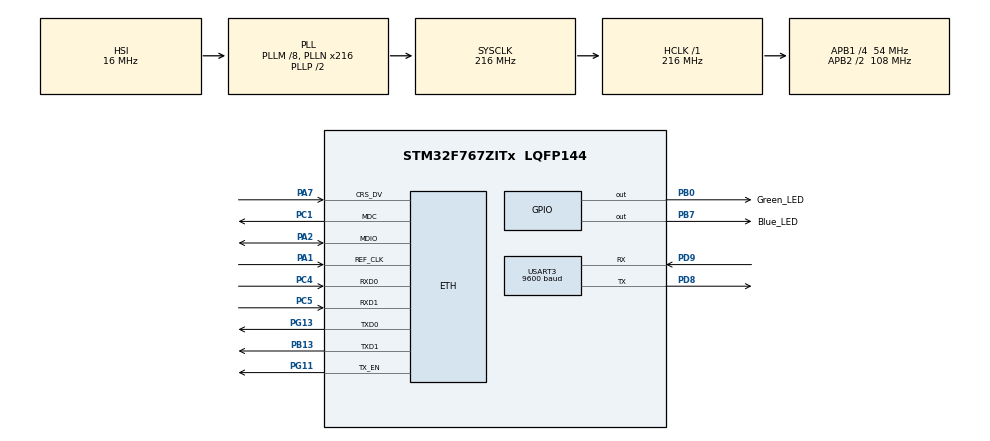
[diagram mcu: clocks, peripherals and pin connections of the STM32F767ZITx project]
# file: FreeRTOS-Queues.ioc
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ETH.MediaInterface=ETH_MEDIA_INTERFACE_RMII
ETH.PhyAddress=0
FREERTOS.Tasks01=defaultTask,24,128,StartDefaultTask,Default,NULL,Dynamic,NULL,NULL
FREERTOS.configUSE_NEWLIB_REENTRANT=1
LWIP.GATEWAY_ADDRESS=192.168.000.001
LWIP.IP_ADDRESS=192.168.000.012
LWIP.LWIP_DHCP=0
LWIP.MEM_SIZE=10*1024
LWIP.NETMASK_ADDRESS=255.255.255.000
LWIP.Version=v2.1.2_Cube
Mcu.Family=STM32F7
Mcu.Name=STM32F767ZITx
Mcu.Package=LQFP144
NVIC.ETH_IRQn=true\:5\:0\:false\:false\:true\:true\:false\:true
NVIC.PriorityGroup=NVIC_PRIORITYGROUP_4
NVIC.TIM1_UP_TIM10_IRQn=true\:15\:0\:false\:false\:true\:false\:false\:true
NVIC.TimeBase=TIM1_UP_TIM10_IRQn
NVIC.TimeBaseIP=TIM1
PA1.Mode=RMII
PA1.Signal=ETH_REF_CLK
PA2.Mode=RMII
PA2.Signal=ETH_MDIO
PA7.Mode=RMII
PA7.Signal=ETH_CRS_DV
PB0.GPIO_Label=Green_LED
PB0.Signal=GPIO_Output
PB13.Mode=RMII
PB13.Signal=ETH_TXD1
PB7.GPIO_Label=Blue_LED
PB7.Signal=GPIO_Output
PC1.Mode=RMII
PC1.Signal=ETH_MDC
PC14/OSC32_IN.Signal=RCC_OSC32_IN
PC15/OSC32_OUT.Signal=RCC_OSC32_OUT
PC4.Mode=RMII
PC4.Signal=ETH_RXD0
PC5.Mode=RMII
PC5.Signal=ETH_RXD1
PD8.Mode=Asynchronous
PD8.Signal=USART3_TX
PD9.Mode=Asynchronous
PD9.Signal=USART3_RX
PG11.Mode=RMII
PG11.Signal=ETH_TX_EN
PG13.Mode=RMII
PG13.Signal=ETH_TXD0
PH0/OSC_IN.Mode=HSE-External-Oscillator
PH0/OSC_IN.Signal=RCC_OSC_IN
PH1/OSC_OUT.Mode=HSE-External-Oscillator
PH1/OSC_OUT.Signal=RCC_OSC_OUT
ProjectManager.HeapSize=0x200
ProjectManager.StackSize=0x400
ProjectManager.TargetToolchain=STM32CubeIDE
RCC.48MHZClocksFreq_Value=24000000
RCC.AHBFreq_Value=216000000
RCC.APB1CLKDivider=RCC_HCLK_DIV4
RCC.APB1Freq_Value=54000000
RCC.APB1TimFreq_Value=108000000
RCC.APB2CLKDivider=RCC_HCLK_DIV2
RCC.APB2Freq_Value=108000000
RCC.APB2TimFreq_Value=216000000
RCC.CortexFreq_Value=216000000
RCC.HCLKFreq_Value=216000000
RCC.HSE_VALUE=16000000
RCC.HSI_VALUE=16000000
RCC.LSE_VALUE=32768
RCC.PLLM=8
RCC.PLLMUL=RCC_PLL_MUL9
RCC.PLLN=216
RCC.PRESCALERUSB=RCC_USBCLKSOURCE_PLL_DIV1_5
RCC.SYSCLKFreq_VALUE=216000000
RCC.SYSCLKSource=RCC_SYSCLKSOURCE_PLLCLK
RCC.SYSCLKSourceVirtual=RCC_SYSCLKSOURCE_PLLCLK
RCC.USBFreq_Value=216000000
RCC.VCOOutputFreq_Value=432000000
USART3.BaudRate=9600
USART3.VirtualMode-Asynchronous=VM_ASYNC
VP_FREERTOS_VS_CMSIS_V2.Mode=CMSIS_V2
VP_LWIP_VS_Enabled.Mode=Enabled
VP_SYS_VS_tim1.Mode=TIM1
board=NUCLEO-F767ZI

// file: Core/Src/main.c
/* USER CODE BEGIN Header */
/**
  ******************************************************************************
  * @file           : main.c
  * @brief          : Main program body
  ******************************************************************************
  * @attention
  *
  * <h2><center>&copy; Copyright (c) 2023 STMicroelectronics.
  * All rights reserved.</center></h2>
  *
  * This software component is licensed by ST under Ultimate Liberty license
  * SLA0044, the "License"; You may not use this file except in compliance with
  * the License. You may obtain a copy of the License at:
  *                             www.st.com/SLA0044
  *
  ******************************************************************************
  */
/* USER CODE END Header */
#include "main.h"
#include "cmsis_os.h"
#include "lwip.h"

/* USER CODE BEGIN Includes */
#include "Queue_Examples.h"

/* USER CODE END Includes */

UART_HandleTypeDef huart3;

/* Definitions for defaultTask */
osThreadId_t defaultTaskHandle;
const osThreadAttr_t defaultTask_attributes = {
  .name = "defaultTask",
  .stack_size = 128 * 4,
  .priority = (osPriority_t) osPriorityIdle,
};
/* USER CODE BEGIN PV */

TaskHandle_t receive_uart_task_handle;
TaskHandle_t send_uart_task_handle;
QueueHandle_t xQueue1 ;

/* USER CODE END PV */

void SystemClock_Config(void);
static void MX_GPIO_Init(void);
static void MX_USART3_UART_Init(void);
void StartDefaultTask(void *argument);

int main(void)
{

  /* MCU Configuration--------------------------------------------------------*/

  /* Reset of all peripherals, Initializes the Flash interface and the Systick. */
  HAL_Init();

  /* Configure the system clock */
  SystemClock_Config();

  /* Initialize all configured peripherals */
  MX_GPIO_Init();
  MX_USART3_UART_Init();

  /* Init scheduler */
  osKernelInitialize();

  /* USER CODE BEGIN RTOS_QUEUES */
  /* add queues, ... */
     xQueue1 = xQueueCreate( 5, sizeof(uint32_t));
	 if(xQueue1 == 0 )
  {
	  Error_Handler();
  }
  /* USER CODE END RTOS_QUEUES */

  /* Create the thread(s) */
  /* creation of defaultTask */
  defaultTaskHandle = osThreadNew(StartDefaultTask, NULL, &defaultTask_attributes);

  /* USER CODE BEGIN RTOS_THREADS */
  /* add threads, ... */

	  if( xTaskCreate(rcv_task,"receive_uart_task",1000,0, 1, &receive_uart_task_handle) != pdPASS)
	   {
	 	  // add an error msg
		  Error_Handler();
	   }

	  if( xTaskCreate(msg_parser,"handler_uart_parser",1000,0,1, &send_uart_task_handle) != pdPASS)
	 	   {
	 	 	  // add an error msg
		  Error_Handler();
	 	   }

  /* USER CODE END RTOS_THREADS */

  /* Start scheduler */
  osKernelStart();

  /* We should never get here as control is now taken by the scheduler */
  /* Infinite loop */
  while (1)
  {

  }
}

void SystemClock_Config(void)
{
  RCC_OscInitTypeDef RCC_OscInitStruct = {0};
  RCC_ClkInitTypeDef RCC_ClkInitStruct = {0};
  RCC_PeriphCLKInitTypeDef PeriphClkInitStruct = {0};

  /** Configure the main internal regulator output voltage
  */
  __HAL_RCC_PWR_CLK_ENABLE();
  __HAL_PWR_VOLTAGESCALING_CONFIG(PWR_REGULATOR_VOLTAGE_SCALE1);
  /** Initializes the RCC Oscillators according to the specified parameters
  * in the RCC_OscInitTypeDef structure.
  */
  RCC_OscInitStruct.OscillatorType = RCC_OSCILLATORTYPE_HSI;
  RCC_OscInitStruct.HSIState = RCC_HSI_ON;
  RCC_OscInitStruct.HSICalibrationValue = RCC_HSICALIBRATION_DEFAULT;
  RCC_OscInitStruct.PLL.PLLState = RCC_PLL_ON;
  RCC_OscInitStruct.PLL.PLLSource = RCC_PLLSOURCE_HSI;
  RCC_OscInitStruct.PLL.PLLM = 8;
  RCC_OscInitStruct.PLL.PLLN = 216;
  RCC_OscInitStruct.PLL.PLLP = RCC_PLLP_DIV2;
  RCC_OscInitStruct.PLL.PLLQ = 2;
  RCC_OscInitStruct.PLL.PLLR = 2;
  if (HAL_RCC_OscConfig(&RCC_OscInitStruct) != HAL_OK)
  {
    Error_Handler();
  }
  /** Activate the Over-Drive mode
  */
  if (HAL_PWREx_EnableOverDrive() != HAL_OK)
  {
    Error_Handler();
  }
  /** Initializes the CPU, AHB and APB buses clocks
  */
  RCC_ClkInitStruct.ClockType = RCC_CLOCKTYPE_HCLK|RCC_CLOCKTYPE_SYSCLK
                              |RCC_CLOCKTYPE_PCLK1|RCC_CLOCKTYPE_PCLK2;
  RCC_ClkInitStruct.SYSCLKSource = RCC_SYSCLKSOURCE_PLLCLK;
  RCC_ClkInitStruct.AHBCLKDivider = RCC_SYSCLK_DIV1;
  RCC_ClkInitStruct.APB1CLKDivider = RCC_HCLK_DIV4;
  RCC_ClkInitStruct.APB2CLKDivider = RCC_HCLK_DIV2;

  if (HAL_RCC_ClockConfig(&RCC_ClkInitStruct, FLASH_LATENCY_7) != HAL_OK)
  {
    Error_Handler();
  }
  PeriphClkInitStruct.PeriphClockSelection = RCC_PERIPHCLK_USART3;
  PeriphClkInitStruct.Usart3ClockSelection = RCC_USART3CLKSOURCE_PCLK1;
  if (HAL_RCCEx_PeriphCLKConfig(&PeriphClkInitStruct) != HAL_OK)
  {
    Error_Handler();
  }
}

static void MX_USART3_UART_Init(void)
{

  huart3.Instance = USART3;
  huart3.Init.BaudRate = 9600;
  huart3.Init.WordLength = UART_WORDLENGTH_8B;
  huart3.Init.StopBits = UART_STOPBITS_1;
  huart3.Init.Parity = UART_PARITY_NONE;
  huart3.Init.Mode = UART_MODE_TX_RX;
  huart3.Init.HwFlowCtl = UART_HWCONTROL_NONE;
  huart3.Init.OverSampling = UART_OVERSAMPLING_16;
  huart3.Init.OneBitSampling = UART_ONE_BIT_SAMPLE_DISABLE;
  huart3.AdvancedInit.AdvFeatureInit = UART_ADVFEATURE_NO_INIT;
  if (HAL_UART_Init(&huart3) != HAL_OK)
  {
    Error_Handler();
  }

}

static void MX_GPIO_Init(void)
{
  GPIO_InitTypeDef GPIO_InitStruct = {0};

  /* GPIO Ports Clock Enable */
  __HAL_RCC_GPIOC_CLK_ENABLE();
  __HAL_RCC_GPIOH_CLK_ENABLE();
  __HAL_RCC_GPIOA_CLK_ENABLE();
  __HAL_RCC_GPIOB_CLK_ENABLE();
  __HAL_RCC_GPIOD_CLK_ENABLE();
  __HAL_RCC_GPIOG_CLK_ENABLE();

  /*Configure GPIO pin Output Level */
  HAL_GPIO_WritePin(GPIOB, Green_LED_Pin|Blue_LED_Pin, GPIO_PIN_RESET);

  /*Configure GPIO pins : Green_LED_Pin Blue_LED_Pin */
  GPIO_InitStruct.Pin = Green_LED_Pin|Blue_LED_Pin;
  GPIO_InitStruct.Mode = GPIO_MODE_OUTPUT_PP;
  GPIO_InitStruct.Pull = GPIO_NOPULL;
  GPIO_InitStruct.Speed = GPIO_SPEED_FREQ_LOW;
  HAL_GPIO_Init(GPIOB, &GPIO_InitStruct);

}

void StartDefaultTask(void *argument)
{
  /* init code for LWIP */
  MX_LWIP_Init();
  for(;;)
  {
    osDelay(1);
  }
}

void HAL_TIM_PeriodElapsedCallback(TIM_HandleTypeDef *htim)
{
  if (htim->Instance == TIM1) {
    HAL_IncTick();
  }
}

void Error_Handler(void)
{
  __disable_irq();
  while (1)
  {
  }
}

/************************ (C) COPYRIGHT STMicroelectronics *****END OF FILE****/
